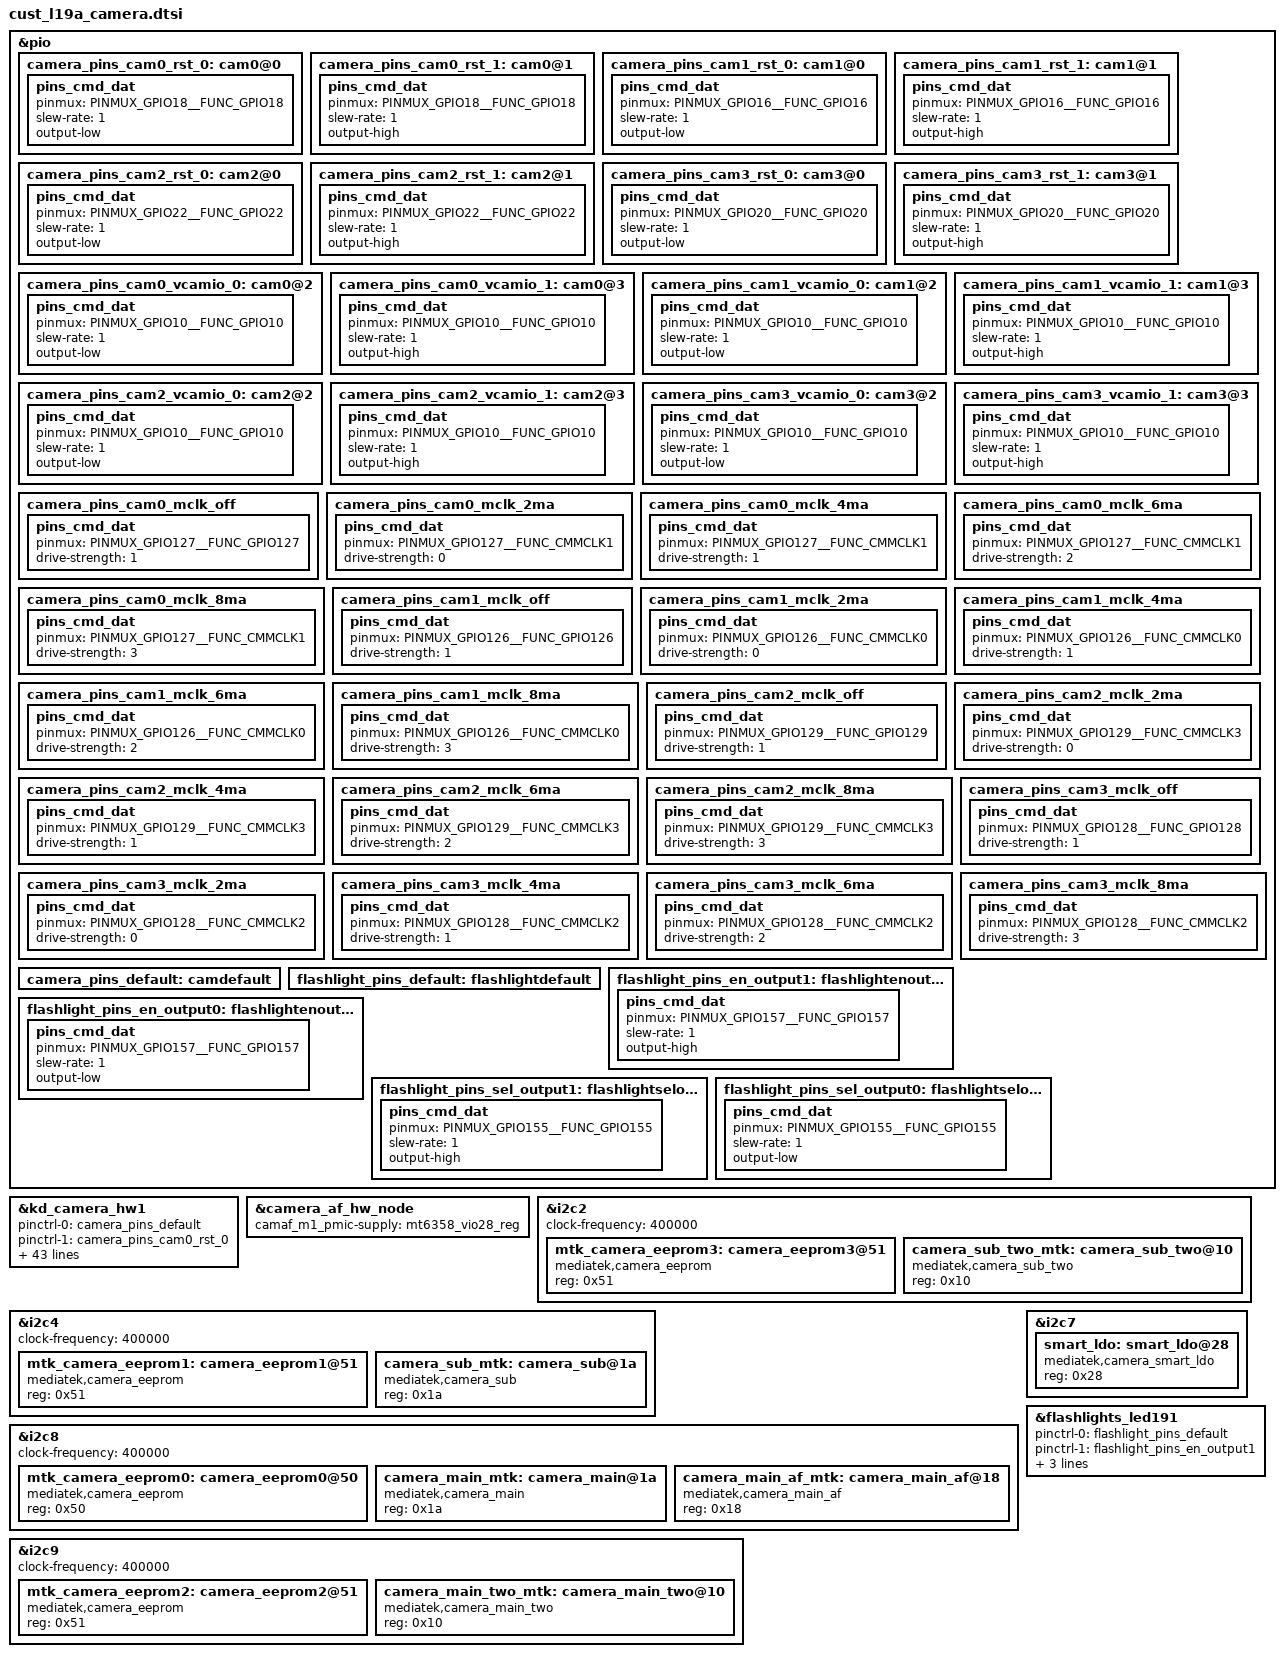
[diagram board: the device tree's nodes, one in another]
// SPDX-License-Identifier: GPL-2.0
/* Copyright (c) 2020 MediaTek Inc. */
/* CAMERA GPIO standardization */
&pio {
	camera_pins_cam0_rst_0: cam0@0 {
		pins_cmd_dat {
			pinmux = <PINMUX_GPIO18__FUNC_GPIO18>;
			slew-rate = <1>;
			output-low;
		};
	};
	camera_pins_cam0_rst_1: cam0@1 {
		pins_cmd_dat {
			pinmux = <PINMUX_GPIO18__FUNC_GPIO18>;
			slew-rate = <1>;
			output-high;
		};
	};
	camera_pins_cam1_rst_0: cam1@0 {
		pins_cmd_dat {
			pinmux = <PINMUX_GPIO16__FUNC_GPIO16>;
			slew-rate = <1>;
			output-low;
		};
	};
	camera_pins_cam1_rst_1: cam1@1 {
		pins_cmd_dat {
			pinmux = <PINMUX_GPIO16__FUNC_GPIO16>;
			slew-rate = <1>;
			output-high;
		};
	};
	camera_pins_cam2_rst_0: cam2@0 {
		pins_cmd_dat {
			pinmux = <PINMUX_GPIO22__FUNC_GPIO22>;
			slew-rate = <1>;
			output-low;
		};
	};
	camera_pins_cam2_rst_1: cam2@1 {
		pins_cmd_dat {
			pinmux = <PINMUX_GPIO22__FUNC_GPIO22>;
			slew-rate = <1>;
			output-high;
		};
	};
	camera_pins_cam3_rst_0: cam3@0 {
		pins_cmd_dat {
			pinmux = <PINMUX_GPIO20__FUNC_GPIO20>;
			slew-rate = <1>;
			output-low;
		};
	};
	camera_pins_cam3_rst_1: cam3@1 {
		pins_cmd_dat {
			pinmux = <PINMUX_GPIO20__FUNC_GPIO20>;
			slew-rate = <1>;
			output-high;
		};
	};
	camera_pins_cam0_vcamio_0: cam0@2 {
		pins_cmd_dat {
			pinmux = <PINMUX_GPIO10__FUNC_GPIO10>;
			slew-rate = <1>;
			output-low;
		};
	};
	camera_pins_cam0_vcamio_1: cam0@3 {
		pins_cmd_dat {
			pinmux = <PINMUX_GPIO10__FUNC_GPIO10>;
			slew-rate = <1>;
			output-high;
		};
	};
	camera_pins_cam1_vcamio_0: cam1@2 {
		pins_cmd_dat {
			pinmux = <PINMUX_GPIO10__FUNC_GPIO10>;
			slew-rate = <1>;
			output-low;
		};
	};
	camera_pins_cam1_vcamio_1: cam1@3 {
		pins_cmd_dat {
			pinmux = <PINMUX_GPIO10__FUNC_GPIO10>;
			slew-rate = <1>;
			output-high;
		};
	};
	camera_pins_cam2_vcamio_0: cam2@2 {
		pins_cmd_dat {
			pinmux = <PINMUX_GPIO10__FUNC_GPIO10>;
			slew-rate = <1>;
			output-low;
		};
	};
	camera_pins_cam2_vcamio_1: cam2@3 {
		pins_cmd_dat {
			pinmux = <PINMUX_GPIO10__FUNC_GPIO10>;
			slew-rate = <1>;
			output-high;
		};
	};
	camera_pins_cam3_vcamio_0: cam3@2 {
		pins_cmd_dat {
			pinmux = <PINMUX_GPIO10__FUNC_GPIO10>;
			slew-rate = <1>;
			output-low;
		};
	};
	camera_pins_cam3_vcamio_1: cam3@3 {
		pins_cmd_dat {
			pinmux = <PINMUX_GPIO10__FUNC_GPIO10>;
			slew-rate = <1>;
			output-high;
		};
	};
	camera_pins_cam0_mclk_off: camera_pins_cam0_mclk_off {
		pins_cmd_dat {
			pinmux = <PINMUX_GPIO127__FUNC_GPIO127>;
			drive-strength = <1>;
		};
	};
	camera_pins_cam0_mclk_2ma: camera_pins_cam0_mclk_2ma {
		pins_cmd_dat {
			pinmux = <PINMUX_GPIO127__FUNC_CMMCLK1>;
			drive-strength = <0>;
		};
	};
	camera_pins_cam0_mclk_4ma: camera_pins_cam0_mclk_4ma {
		pins_cmd_dat {
			pinmux = <PINMUX_GPIO127__FUNC_CMMCLK1>;
			drive-strength = <1>;
		};
	};
	camera_pins_cam0_mclk_6ma: camera_pins_cam0_mclk_6ma {
		pins_cmd_dat {
			pinmux = <PINMUX_GPIO127__FUNC_CMMCLK1>;
			drive-strength = <2>;
		};
	};
	camera_pins_cam0_mclk_8ma: camera_pins_cam0_mclk_8ma {
		pins_cmd_dat {
			pinmux = <PINMUX_GPIO127__FUNC_CMMCLK1>;
			drive-strength = <3>;
		};
	};
	camera_pins_cam1_mclk_off: camera_pins_cam1_mclk_off {
		pins_cmd_dat {
			pinmux = <PINMUX_GPIO126__FUNC_GPIO126>;
			drive-strength = <1>;
		};
	};
	camera_pins_cam1_mclk_2ma: camera_pins_cam1_mclk_2ma {
		pins_cmd_dat {
			pinmux = <PINMUX_GPIO126__FUNC_CMMCLK0>;
			drive-strength = <0>;
		};
	};
	camera_pins_cam1_mclk_4ma: camera_pins_cam1_mclk_4ma {
		pins_cmd_dat {
			pinmux = <PINMUX_GPIO126__FUNC_CMMCLK0>;
			drive-strength = <1>;
		};
	};
	camera_pins_cam1_mclk_6ma: camera_pins_cam1_mclk_6ma {
		pins_cmd_dat {
			pinmux = <PINMUX_GPIO126__FUNC_CMMCLK0>;
			drive-strength = <2>;
		};
	};
	camera_pins_cam1_mclk_8ma: camera_pins_cam1_mclk_8ma {
		pins_cmd_dat {
			pinmux = <PINMUX_GPIO126__FUNC_CMMCLK0>;
			drive-strength = <3>;
		};
	};
	camera_pins_cam2_mclk_off: camera_pins_cam2_mclk_off {
		pins_cmd_dat {
			pinmux = <PINMUX_GPIO129__FUNC_GPIO129>;
			drive-strength = <1>;
		};
	};
	camera_pins_cam2_mclk_2ma: camera_pins_cam2_mclk_2ma {
		pins_cmd_dat {
			pinmux = <PINMUX_GPIO129__FUNC_CMMCLK3>;
			drive-strength = <0>;
		};
	};
	camera_pins_cam2_mclk_4ma: camera_pins_cam2_mclk_4ma {
		pins_cmd_dat {
			pinmux = <PINMUX_GPIO129__FUNC_CMMCLK3>;
			drive-strength = <1>;
		};
	};
	camera_pins_cam2_mclk_6ma: camera_pins_cam2_mclk_6ma {
		pins_cmd_dat {
			pinmux = <PINMUX_GPIO129__FUNC_CMMCLK3>;
			drive-strength = <2>;
		};
	};
	camera_pins_cam2_mclk_8ma: camera_pins_cam2_mclk_8ma {
		pins_cmd_dat {
			pinmux = <PINMUX_GPIO129__FUNC_CMMCLK3>;
			drive-strength = <3>;
		};
	};
    camera_pins_cam3_mclk_off: camera_pins_cam3_mclk_off {
		pins_cmd_dat {
			pinmux = <PINMUX_GPIO128__FUNC_GPIO128>;
			drive-strength = <1>;
		};
	};
	camera_pins_cam3_mclk_2ma: camera_pins_cam3_mclk_2ma {
		pins_cmd_dat {
			pinmux = <PINMUX_GPIO128__FUNC_CMMCLK2>;
			drive-strength = <0>;
		};
	};
	camera_pins_cam3_mclk_4ma: camera_pins_cam3_mclk_4ma {
		pins_cmd_dat {
			pinmux = <PINMUX_GPIO128__FUNC_CMMCLK2>;
			drive-strength = <1>;
		};
	};
	camera_pins_cam3_mclk_6ma: camera_pins_cam3_mclk_6ma {
		pins_cmd_dat {
			pinmux = <PINMUX_GPIO128__FUNC_CMMCLK2>;
			drive-strength = <2>;
		};
	};
	camera_pins_cam3_mclk_8ma: camera_pins_cam3_mclk_8ma {
		pins_cmd_dat {
			pinmux = <PINMUX_GPIO128__FUNC_CMMCLK2>;
			drive-strength = <3>;
		};
	};
	camera_pins_default: camdefault {
	};
};
&kd_camera_hw1 {
	pinctrl-names = "default",
			"cam0_rst0", "cam0_rst1",
			"cam1_rst0", "cam1_rst1",
			"cam2_rst0", "cam2_rst1",
			"cam3_rst0", "cam3_rst1",
            "cam0_ldo_vcamio_0","cam0_ldo_vcamio_1",
            "cam1_ldo_vcamio_0","cam1_ldo_vcamio_1",
            "cam2_ldo_vcamio_0","cam2_ldo_vcamio_1",
            "cam3_ldo_vcamio_0","cam3_ldo_vcamio_1",
			"cam0_mclk_off",
			"cam0_mclk_2mA", "cam0_mclk_4mA",
			"cam0_mclk_6mA", "cam0_mclk_8mA",
			"cam1_mclk_off",
			"cam1_mclk_2mA", "cam1_mclk_4mA",
			"cam1_mclk_6mA", "cam1_mclk_8mA",
			"cam2_mclk_off",
			"cam2_mclk_2mA", "cam2_mclk_4mA",
			"cam2_mclk_6mA", "cam2_mclk_8mA",
			"cam3_mclk_off",
			"cam3_mclk_2mA", "cam3_mclk_4mA",
			"cam3_mclk_6mA", "cam3_mclk_8mA";

	pinctrl-0 = <&camera_pins_default>;
	pinctrl-1 = <&camera_pins_cam0_rst_0>;
	pinctrl-2 = <&camera_pins_cam0_rst_1>;
	pinctrl-3 = <&camera_pins_cam1_rst_0>;
	pinctrl-4 = <&camera_pins_cam1_rst_1>;
	pinctrl-5 = <&camera_pins_cam2_rst_0>;
	pinctrl-6 = <&camera_pins_cam2_rst_1>;
	pinctrl-7 = <&camera_pins_cam3_rst_0>;
	pinctrl-8 = <&camera_pins_cam3_rst_1>;

    pinctrl-9 = <&camera_pins_cam0_vcamio_0>;
    pinctrl-10 = <&camera_pins_cam0_vcamio_1>;
    pinctrl-11 = <&camera_pins_cam1_vcamio_0>;
    pinctrl-12 = <&camera_pins_cam1_vcamio_1>;
    pinctrl-13 = <&camera_pins_cam2_vcamio_0>;
    pinctrl-14 = <&camera_pins_cam2_vcamio_1>;
    pinctrl-15 = <&camera_pins_cam3_vcamio_0>;
    pinctrl-16 = <&camera_pins_cam3_vcamio_1>;

	pinctrl-17 = <&camera_pins_cam0_mclk_off>;
	pinctrl-18 = <&camera_pins_cam0_mclk_2ma>;
	pinctrl-19 = <&camera_pins_cam0_mclk_4ma>;
	pinctrl-20 = <&camera_pins_cam0_mclk_6ma>;
	pinctrl-21 = <&camera_pins_cam0_mclk_8ma>;
	pinctrl-22 = <&camera_pins_cam1_mclk_off>;
	pinctrl-23 = <&camera_pins_cam1_mclk_2ma>;
	pinctrl-24 = <&camera_pins_cam1_mclk_4ma>;
	pinctrl-25 = <&camera_pins_cam1_mclk_6ma>;
	pinctrl-26 = <&camera_pins_cam1_mclk_8ma>;
	pinctrl-27 = <&camera_pins_cam2_mclk_off>;
	pinctrl-28 = <&camera_pins_cam2_mclk_2ma>;
	pinctrl-29 = <&camera_pins_cam2_mclk_4ma>;
	pinctrl-30 = <&camera_pins_cam2_mclk_6ma>;
	pinctrl-31 = <&camera_pins_cam2_mclk_8ma>;
	pinctrl-32 = <&camera_pins_cam3_mclk_off>;
	pinctrl-33 = <&camera_pins_cam3_mclk_2ma>;
	pinctrl-34 = <&camera_pins_cam3_mclk_4ma>;
	pinctrl-35 = <&camera_pins_cam3_mclk_6ma>;
	pinctrl-36 = <&camera_pins_cam3_mclk_8ma>;

	status = "okay";
    cam0_enable_sensor = "s5kjn1_sunny_main_mipi_raw s5kjn1_ofilm_main_mipi_raw";
    cam1_enable_sensor = "ov8856_aac_front_mipi_raw ov8856_ofilm_front_mipi_raw gc5035_sunny_front_mipi_raw hi556_ofilm_front_mipi_raw";
    cam2_enable_sensor = "ov02b1b_sunny_depth_mipi_raw sc202cs_ofilm_depth_mipi_raw";
    cam3_enable_sensor = "gc02m1_ofilm_macro_mipi_raw gc02m1_aac_macro_mipi_raw";
};
/* CAMERA GPIO end */

/* main af */
&camera_af_hw_node {
    camaf_m1_pmic-supply = <&mt6358_vio28_reg>;
};
/* CAMERA EEPROM */
&i2c2 {
	status = "okay";
	clock-frequency = <400000>;
	#address-cells = <1>;
	#size-cells = <0>;

	mtk_camera_eeprom3:camera_eeprom3@51 {
		compatible = "mediatek,camera_eeprom";
		reg = <0x51>;
		status = "okay";
	};
	camera_sub_two_mtk:camera_sub_two@10 {
		compatible = "mediatek,camera_sub_two";
		#thermal-sensor-cells = <0>;
		reg = <0x10>;
		status = "okay";
	};
};
&i2c4 {
	status = "okay";
	clock-frequency = <400000>;
	#address-cells = <1>;
	#size-cells = <0>;

	mtk_camera_eeprom1:camera_eeprom1@51 {
		compatible = "mediatek,camera_eeprom";
		reg = <0x51>;
		status = "okay";
	};
	camera_sub_mtk:camera_sub@1a {
		compatible = "mediatek,camera_sub";
		#thermal-sensor-cells = <0>;
		reg = <0x1a>;
		status = "okay";
	};
};
&i2c8 {
	status = "okay";
	clock-frequency = <400000>;
	#address-cells = <1>;
	#size-cells = <0>;

	mtk_camera_eeprom0:camera_eeprom0@50 {
		compatible = "mediatek,camera_eeprom";
		reg = <0x50>;
		status = "okay";
	};
	camera_main_mtk:camera_main@1a {
		compatible = "mediatek,camera_main";
		#thermal-sensor-cells = <0>;
		reg = <0x1a>;
		status = "okay";
	};
	camera_main_af_mtk:camera_main_af@18 {
		compatible = "mediatek,camera_main_af";
		reg = <0x18>;
		status = "okay";
	};
};
&i2c9 {
	status = "okay";
	clock-frequency = <400000>;
	#address-cells = <1>;
	#size-cells = <0>;

	mtk_camera_eeprom2:camera_eeprom2@51 {
		compatible = "mediatek,camera_eeprom";
		reg = <0x51>;
		status = "okay";
	};
	camera_main_two_mtk:camera_main_two@10 {
		compatible = "mediatek,camera_main_two";
		#thermal-sensor-cells = <0>;
		reg = <0x10>;
		status = "okay";
	};
};
/* CAMERA EEPROM end */

/* CAMERA SMART LDO */
&i2c7 {
    smart_ldo:smart_ldo@28 {
        compatible = "mediatek,camera_smart_ldo";
		reg = <0x28>;
		status = "okay";
	};
};
/* CAMERA SMART LDO  end */

/* CAMERA FLASHLIGHT */
&flashlights_led191 {
        pinctrl-names = "default", "hw_ch0_high",
                "hw_ch0_low", "hw_ch1_high",
                "hw_ch1_low";
        pinctrl-0 = <&flashlight_pins_default>;
        pinctrl-1 = <&flashlight_pins_en_output1>;
        pinctrl-2 = <&flashlight_pins_en_output0>;
        pinctrl-3 = <&flashlight_pins_sel_output1>;
        pinctrl-4 = <&flashlight_pins_sel_output0>;
        status = "okay";
};
&pio {
        flashlight_pins_default: flashlightdefault {
        };
        flashlight_pins_en_output1: flashlightenoutput1 {
                pins_cmd_dat {
                        pinmux = <PINMUX_GPIO157__FUNC_GPIO157>;
                        slew-rate = <1>;
                        output-high;
                };
        };
        flashlight_pins_en_output0: flashlightenoutput0 {
                pins_cmd_dat {
                        pinmux = <PINMUX_GPIO157__FUNC_GPIO157>;
                        slew-rate = <1>;
                        output-low;
                };
        };
        flashlight_pins_sel_output1: flashlightseloutput1 {
                pins_cmd_dat {
                        pinmux = <PINMUX_GPIO155__FUNC_GPIO155>;
                        slew-rate = <1>;
                        output-high;
                };
        };
        flashlight_pins_sel_output0: flashlightseloutput0 {
                pins_cmd_dat {
                        pinmux = <PINMUX_GPIO155__FUNC_GPIO155>;
                        slew-rate = <1>;
                        output-low;
                };
        };
};
/* CAMERA FLASHLIGHT end */
